VERSION ""

NS_ :

BS_:

BU_: RaceBoxCompanion

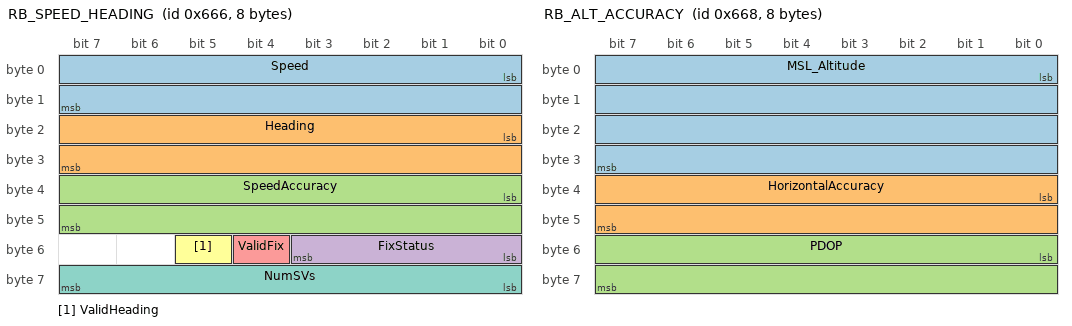
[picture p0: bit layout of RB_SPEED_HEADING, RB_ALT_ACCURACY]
BO_ 1638 RB_SPEED_HEADING: 8 RaceBoxCompanion
 SG_ Speed : 0|16@1+ (0.01,0) [0|655.35] "km/h" Vector__XXX
 SG_ Heading : 16|16@1+ (0.01,0) [0|359.99] "deg" Vector__XXX
 SG_ SpeedAccuracy : 32|16@1+ (0.01,0) [0|655.35] "km/h" Vector__XXX
 SG_ FixStatus : 48|4@1+ (1,0) [0|15] "" Vector__XXX
 SG_ ValidFix : 52|1@1+ (1,0) [0|1] "" Vector__XXX
 SG_ ValidHeading : 53|1@1+ (1,0) [0|1] "" Vector__XXX
 SG_ NumSVs : 56|8@1+ (1,0) [0|255] "" Vector__XXX

BO_ 1639 RB_LAT_LON: 8 RaceBoxCompanion
 SG_ Latitude : 0|32@1- (1E-07,0) [-90|90] "deg" Vector__XXX
 SG_ Longitude : 32|32@1- (1E-07,0) [-180|180] "deg" Vector__XXX

BO_ 1640 RB_ALT_ACCURACY: 8 RaceBoxCompanion
 SG_ MSL_Altitude : 0|32@1- (0.001,0) [-1000|20000] "m" Vector__XXX
 SG_ HorizontalAccuracy : 32|16@1+ (0.01,0) [0|655.35] "m" Vector__XXX
 SG_ PDOP : 48|16@1+ (0.01,0) [0|655.35] "" Vector__XXX

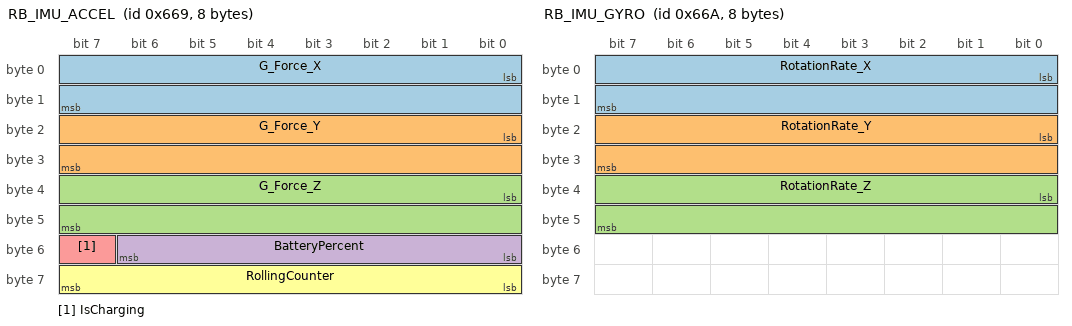
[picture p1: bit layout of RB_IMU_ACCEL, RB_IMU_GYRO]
BO_ 1641 RB_IMU_ACCEL: 8 RaceBoxCompanion
 SG_ G_Force_X : 0|16@1- (0.001,0) [-32.768|32.767] "g" Vector__XXX
 SG_ G_Force_Y : 16|16@1- (0.001,0) [-32.768|32.767] "g" Vector__XXX
 SG_ G_Force_Z : 32|16@1- (0.001,0) [-32.768|32.767] "g" Vector__XXX
 SG_ BatteryPercent : 48|7@1+ (1,0) [0|100] "%" Vector__XXX
 SG_ IsCharging : 55|1@1+ (1,0) [0|1] "" Vector__XXX
 SG_ RollingCounter : 56|8@1+ (1,0) [0|255] "" Vector__XXX

BO_ 1642 RB_IMU_GYRO: 8 RaceBoxCompanion
 SG_ RotationRate_X : 0|16@1- (0.01,0) [-327.68|327.67] "deg/s" Vector__XXX
 SG_ RotationRate_Y : 16|16@1- (0.01,0) [-327.68|327.67] "deg/s" Vector__XXX
 SG_ RotationRate_Z : 32|16@1- (0.01,0) [-327.68|327.67] "deg/s" Vector__XXX

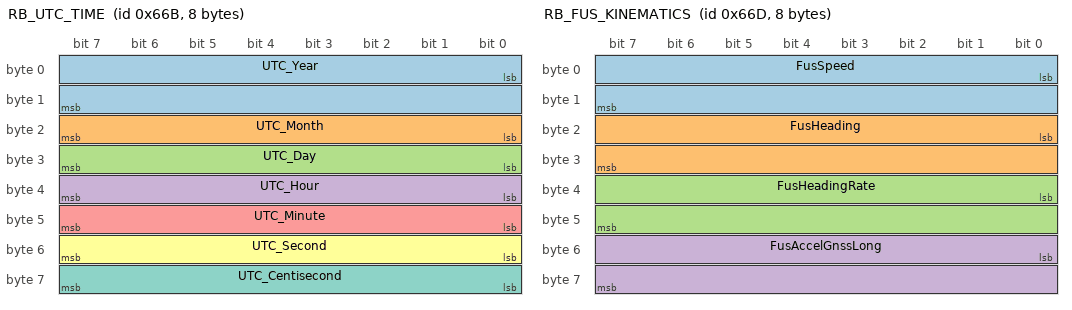
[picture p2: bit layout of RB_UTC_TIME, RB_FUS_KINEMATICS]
BO_ 1643 RB_UTC_TIME: 8 RaceBoxCompanion
 SG_ UTC_Year : 0|16@1+ (1,0) [2000|2099] "year" Vector__XXX
 SG_ UTC_Month : 16|8@1+ (1,0) [1|12] "month" Vector__XXX
 SG_ UTC_Day : 24|8@1+ (1,0) [1|31] "day" Vector__XXX
 SG_ UTC_Hour : 32|8@1+ (1,0) [0|23] "h" Vector__XXX
 SG_ UTC_Minute : 40|8@1+ (1,0) [0|59] "min" Vector__XXX
 SG_ UTC_Second : 48|8@1+ (1,0) [0|59] "s" Vector__XXX
 SG_ UTC_Centisecond : 56|8@1+ (0.01,0) [0|0.99] "s" Vector__XXX

BO_ 1644 RB_FUS_STATE: 8 RaceBoxCompanion
 SG_ FusState : 0|3@1+ (1,0) [0|4] "" Vector__XXX
 SG_ FusLevelSource : 3|2@1+ (1,0) [0|3] "" Vector__XXX
 SG_ FusYawResolved : 5|1@1+ (1,0) [0|1] "" Vector__XXX
 SG_ FusStationary : 6|1@1+ (1,0) [0|1] "" Vector__XXX
 SG_ FusGnssOk : 7|1@1+ (1,0) [0|1] "" Vector__XXX
 SG_ FusSpeedValid : 8|1@1+ (1,0) [0|1] "" Vector__XXX
 SG_ FusHeadingOk : 9|1@1+ (1,0) [0|1] "" Vector__XXX
 SG_ FusYawLongValid : 10|1@1+ (1,0) [0|1] "" Vector__XXX
 SG_ FusYawLatValid : 11|1@1+ (1,0) [0|1] "" Vector__XXX
 SG_ FusStandstillValid : 12|1@1+ (1,0) [0|1] "" Vector__XXX
 SG_ FusCruiseValid : 13|1@1+ (1,0) [0|1] "" Vector__XXX
 SG_ FusConfidence : 16|8@1+ (1,0) [0|100] "%" Vector__XXX
 SG_ FusLevelConfidence : 24|8@1+ (1,0) [0|100] "%" Vector__XXX
 SG_ FusYawConfidence : 32|8@1+ (1,0) [0|100] "%" Vector__XXX
 SG_ FusInputScore : 40|8@1+ (1,0) [0|100] "%" Vector__XXX
 SG_ FusStopsCount : 48|4@1+ (1,0) [0|15] "" Vector__XXX
 SG_ FusLevelOutliers : 52|4@1+ (1,0) [0|15] "" Vector__XXX
 SG_ FusRollingCounter : 56|8@1+ (1,0) [0|255] "" Vector__XXX

BO_ 1645 RB_FUS_KINEMATICS: 8 RaceBoxCompanion
 SG_ FusSpeed : 0|16@1+ (0.01,0) [0|655.35] "km/h" Vector__XXX
 SG_ FusHeading : 16|16@1+ (0.01,0) [0|655.35] "deg" Vector__XXX
 SG_ FusHeadingRate : 32|16@1- (0.01,0) [-327.68|327.67] "deg/s" Vector__XXX
 SG_ FusAccelGnssLong : 48|16@1- (0.001,0) [-32.768|32.767] "g" Vector__XXX

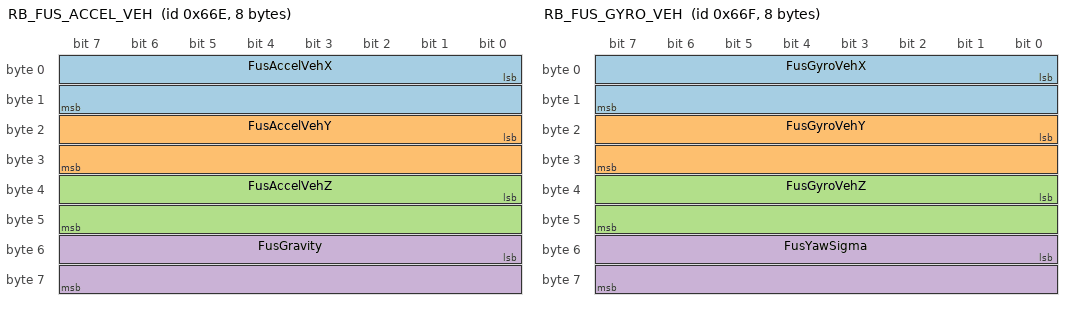
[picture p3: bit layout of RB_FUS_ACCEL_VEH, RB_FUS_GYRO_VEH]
BO_ 1646 RB_FUS_ACCEL_VEH: 8 RaceBoxCompanion
 SG_ FusAccelVehX : 0|16@1- (0.001,0) [-32.768|32.767] "g" Vector__XXX
 SG_ FusAccelVehY : 16|16@1- (0.001,0) [-32.768|32.767] "g" Vector__XXX
 SG_ FusAccelVehZ : 32|16@1- (0.001,0) [-32.768|32.767] "g" Vector__XXX
 SG_ FusGravity : 48|16@1+ (0.001,0) [0|65.535] "g" Vector__XXX

BO_ 1647 RB_FUS_GYRO_VEH: 8 RaceBoxCompanion
 SG_ FusGyroVehX : 0|16@1- (0.01,0) [-327.68|327.67] "deg/s" Vector__XXX
 SG_ FusGyroVehY : 16|16@1- (0.01,0) [-327.68|327.67] "deg/s" Vector__XXX
 SG_ FusGyroVehZ : 32|16@1- (0.01,0) [-327.68|327.67] "deg/s" Vector__XXX
 SG_ FusYawSigma : 48|16@1+ (0.01,0) [0|655.35] "deg" Vector__XXX

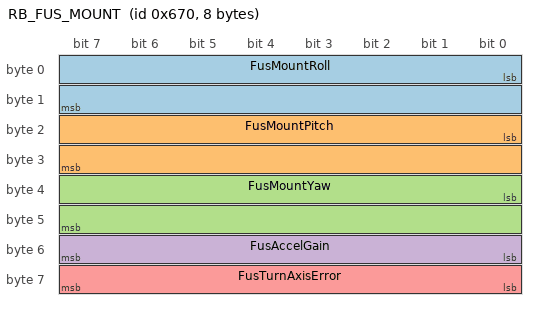
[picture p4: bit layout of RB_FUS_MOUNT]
BO_ 1648 RB_FUS_MOUNT: 8 RaceBoxCompanion
 SG_ FusMountRoll : 0|16@1- (0.01,0) [-327.68|327.67] "deg" Vector__XXX
 SG_ FusMountPitch : 16|16@1- (0.01,0) [-327.68|327.67] "deg" Vector__XXX
 SG_ FusMountYaw : 32|16@1- (0.01,0) [-327.68|327.67] "deg" Vector__XXX
 SG_ FusAccelGain : 48|8@1+ (0.01,0) [0|2.55] "" Vector__XXX
 SG_ FusTurnAxisError : 56|8@1+ (1,0) [0|255] "deg" Vector__XXX

CM_ BO_ 1638 "RaceBox GPS Speed, Course Heading, Fix Quality, and Satellites in view";
CM_ BO_ 1639 "RaceBox GPS High-Precision Latitude and Longitude Coordinates (WGS84)";
CM_ BO_ 1640 "RaceBox GPS MSL Altitude, Horizontal Positional Accuracy, and PDOP";
CM_ BO_ 1641 "RaceBox 3-Axis Accelerometer (G-force), Battery Percentage, and Rolling Counter";
CM_ BO_ 1642 "RaceBox 3-Axis Gyroscope Angular Rotation Rates (Roll, Pitch, Yaw)";
CM_ BO_ 1643 "RaceBox GPS UTC Date, Time of Day, and Fractional Centiseconds";
VAL_ 1638 FixStatus 0 "NoFix" 2 "2D_Fix" 3 "3D_Fix" ;
VAL_ 1638 ValidFix 0 "Invalid" 1 "Valid" ;
VAL_ 1638 ValidHeading 0 "Invalid" 1 "Valid" ;
VAL_ 1641 IsCharging 0 "Discharging" 1 "Charging" ;
CM_ BO_ 1644 "Optional (fusion enabled): alignment state machine, validity flags, plausibility scores, rolling counter shared with RB_IMU_ACCEL";
CM_ BO_ 1645 "Optional (fusion enabled): filtered speed, heading of motion, heading rate (clockwise positive) and GNSS-derived longitudinal acceleration";
CM_ BO_ 1646 "Optional (fusion enabled): specific force in the vehicle frame (X forward, Y left, Z up) and learned gravity norm";
CM_ BO_ 1647 "Optional (fusion enabled): bias-corrected angular rate in the vehicle frame (yaw positive for left turns) and yaw 1-sigma";
CM_ BO_ 1648 "Optional (fusion enabled): receiver mounting roll/pitch/yaw, accelerometer gain and cornering-axis error (255 = not enough turns yet)";
CM_ SG_ 1647 FusYawSigma "655.35 = unknown";
CM_ SG_ 1648 FusAccelGain "0 = unknown";
VAL_ 1644 FusState 0 "Unaligned" 1 "LevelCoarse" 2 "Leveled" 3 "Aligned" 4 "Degraded" ;
VAL_ 1644 FusLevelSource 0 "None" 1 "Cruise" 2 "Standstill" 3 "Blend" ;
